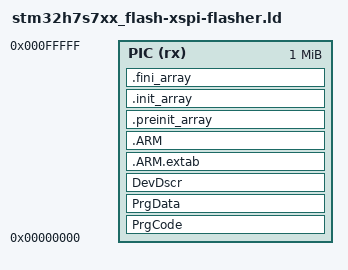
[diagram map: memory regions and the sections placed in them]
/*
******************************************************************************
**
** @file        : LinkerScript.ld
**
** @author      : Auto-generated by STM32CubeIDE
**
** @brief       : Linker script for STM32H7S7xx Device from STM32H7RS series
**                      64Kbytes FLASH
**                      456Kbytes RAM
**
**                Set heap size, stack size and stack location according
**                to application requirements.
**
**                Set memory bank area and size if external memory is used
**
**  Target      : STMicroelectronics STM32
**
**  Distribution: The file is distributed as is, without any warranty
**                of any kind.
**
******************************************************************************
** @attention
**
** Copyright (c) 2023 STMicroelectronics.
** All rights reserved.
**
** This software is licensed under terms that can be found in the LICENSE file
** in the root directory of this software component.
** If no LICENSE file comes with this software, it is provided AS-IS.
**
******************************************************************************
*/

/* Specify the memory areas - we do not allow .data sections */
MEMORY
{
  PIC (rx) : ORIGIN = 0, LENGTH = 1024K
}

/* Define output sections */
SECTIONS
{
  PrgCode :
  {
    . = ALIGN(4);
    KEEP(*(.text))           /* .text sections (code) */
    KEEP(*(.text*))          /* .text* sections (code) */
    KEEP(*(.glue_7))         /* glue arm to thumb code */
    KEEP(*(.glue_7t))        /* glue thumb to arm code */
    KEEP(*(.eh_frame))

    KEEP (*(.init))
    KEEP (*(.fini))

    . = ALIGN(4);
    _etext = .;        /* define a global symbols at end of code */
  } >PIC

  PrgData :
  {
    . = ALIGN(4);
    KEEP(*(.rodata))         /* .rodata sections (constants, strings, etc.) */
    KEEP(*(.rodata*))        /* .rodata* sections (constants, strings, etc.) */
    . = ALIGN(4);
  } >PIC

  DevDscr :
  {
    . = ALIGN(4);
    KEEP(*(.desc))
  } >PIC

  .ARM.extab   : { *(.ARM.extab* .gnu.linkonce.armextab.*) } >PIC
  .ARM : {
    __exidx_start = .;
    *(.ARM.exidx*)
    __exidx_end = .;
  } >PIC

  .preinit_array     :
  {
    PROVIDE_HIDDEN (__preinit_array_start = .);
    KEEP (*(.preinit_array*))
    PROVIDE_HIDDEN (__preinit_array_end = .);
  } >PIC
  .init_array :
  {
    PROVIDE_HIDDEN (__init_array_start = .);
    KEEP (*(SORT(.init_array.*)))
    KEEP (*(.init_array*))
    PROVIDE_HIDDEN (__init_array_end = .);
  } >PIC
  .fini_array :
  {
    PROVIDE_HIDDEN (__fini_array_start = .);
    KEEP (*(SORT(.fini_array.*)))
    KEEP (*(.fini_array*))
    PROVIDE_HIDDEN (__fini_array_end = .);
  } >PIC
  
  /DISCARD/ :
  {
    libc.a ( * )
    libm.a ( * )
    libgcc.a ( * )
  }

  .ARM.attributes 0 : { *(.ARM.attributes) }
}

